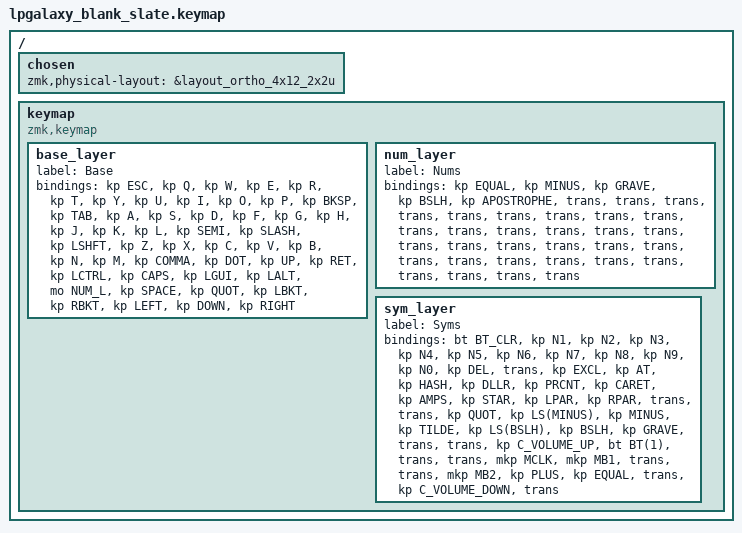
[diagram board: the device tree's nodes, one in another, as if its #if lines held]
/*
 * Copyright (c) 2022 Pete Johanson
 *
 * SPDX-License-Identifier: MIT
 */

#include <behaviors.dtsi>
#include <dt-bindings/zmk/keys.h>
#include <dt-bindings/zmk/bt.h>
#include <dt-bindings/zmk/outputs.h>
#include <dt-bindings/zmk/mouse.h>


#define QWERTY_BASE 1

#define TBLE_ORTHO   1
// #define TBLE_MIT     1
// #define TBLE_DUAL_2U 1

#define NAV_L 1
#define NUM_L 2
#define SYM_L 3

#define BT(n) BT_SEL n

/ {
    chosen {
       zmk,physical-layout =
#ifdef TBLE_DUAL_2U
                       &layout_ortho_4x12_2x2u;
#elif defined(TBLE_MIT)
                       &layout_ortho_4x12_1x2u;
#else
                       &layout_ortho_4x12_all1u;
#endif
    };

    keymap {
        compatible = "zmk,keymap";

        base_layer {
            label = "Base";
            bindings = <
 &kp ESC    &kp Q      &kp W      &kp E       &kp R      &kp T      &kp Y      &kp U      &kp I     &kp O     &kp P     &kp BKSP
 &kp TAB    &kp A      &kp S      &kp D       &kp F      &kp G      &kp H      &kp J      &kp K     &kp L     &kp SEMI  &kp SLASH
 &kp LSHFT  &kp Z      &kp X      &kp C       &kp V      &kp B      &kp N      &kp M      &kp COMMA &kp DOT   &kp UP    &kp RET
 &kp LCTRL  &kp CAPS   &kp LGUI   &kp LALT    &mo NUM_L  &kp SPACE  &kp QUOT  &kp LBKT   &kp RBKT   &kp LEFT  &kp DOWN  &kp RIGHT
            >;
        };

        num_layer {
            label = "Nums";
            bindings = <

 &kp EQUAL   &kp MINUS  &kp GRAVE  &kp BSLH   &kp APOSTROPHE     &trans     &trans     &trans     &trans     &trans     &trans     &trans
 &trans     &trans     &trans     &trans     &trans     &trans     &trans     &trans     &trans     &trans     &trans     &trans
 &trans     &trans     &trans     &trans     &trans     &trans     &trans     &trans     &trans     &trans     &trans     &trans
            >;
        };

        sym_layer {
            label = "Syms";
            bindings = <
&bt BT_CLR  &kp N1     &kp N2     &kp N3     &kp N4     &kp N5     &kp N6     &kp N7     &kp N8     &kp N9     &kp N0     &kp DEL     
&trans      &kp EXCL   &kp AT     &kp HASH   &kp DLLR   &kp PRCNT  &kp CARET  &kp AMPS   &kp STAR   &kp LPAR   &kp RPAR   &trans     
&trans &kp QUOT  &kp LS(MINUS) &kp MINUS &kp TILDE &kp LS(BSLH)   &kp BSLH     &kp GRAVE     &trans     &trans     &kp C_VOLUME_UP     &bt BT(1)    
 &trans     &trans     &mkp MCLK     &mkp MB1     &trans     &trans     &mkp MB2  &kp PLUS     &kp EQUAL     &trans     &kp C_VOLUME_DOWN     &trans
            >;
        };
    };
};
